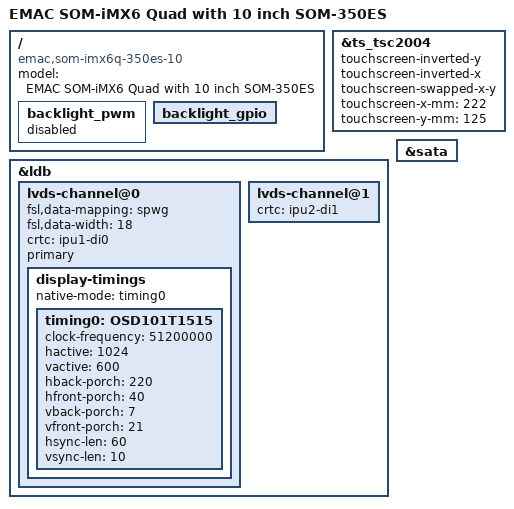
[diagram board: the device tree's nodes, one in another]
/*
 * Copyright 2022 EMAC Inc.
 *
 * Author: Joseph Mills <jmills@emacinc.com>
 *
 * This program is free software; you can redistribute it and/or modify
 * it under the terms of the GNU General Public License version 2 as
 * published by the Free Software Foundation.
 *
 */

/dts-v1/;

#include <dt-bindings/interrupt-controller/irq.h>
#include "imx6q.dtsi"
#include "som-imx6q-350es.dts"

/ {
    model = "EMAC SOM-iMX6 Quad with 10 inch SOM-350ES";
    compatible = "emac,som-imx6q-350es-10", "fsl,imx6q";
    // 7 inch
    backlight_pwm: backlight_pwm {
        status = "disabled";
    };
    // 10 inch
    backlight_gpio: backlight_gpio {
        status = "okay";
    };
};

&ts_tsc2004{
    touchscreen-inverted-y;
    touchscreen-inverted-x;
    touchscreen-swapped-x-y;
    touchscreen-x-mm = <222>;
    touchscreen-y-mm = <125>;
};

&ldb {
    status = "okay";
    lvds-channel@0 {
        fsl,data-mapping = "spwg";
        fsl,data-width = <18>;        
        crtc = "ipu1-di0";
        primary;
        status = "okay";
        display-timings {
            native-mode = <&timing0>;
            timing0: OSD101T1515 {
                clock-frequency = <51200000>;
                hactive = <1024>;
                vactive = <600>;
                hback-porch = <220>;
                hfront-porch = <40>;
                vback-porch = <7>;
                vfront-porch = <21>;
                hsync-len = <60>;
                vsync-len = <10>;
            };
        };
    };
    lvds-channel@1 {
        crtc = "ipu2-di1";
    };
};


&sata {
    status = "okay";
};
